# MC3_IPGW_ICONT register map
Vendor: Texas Instruments
Peripheral module from a debugger description file (folder DRA74xP_75xP_76xP_77xP).
Registers are 32-bit, access not given, reset 0x0 unless marked. A register's access mark holds for its fields unless they carry their own. Offsets are as the file gives them; lines under a group give offsets from that group; [hi:lo] are bit positions; {n}, {i} and the like mark numbered series; 'fields as' and 'values as' point back to an identical list; <NAME> marks a mode.

## MC3_IPGW_ICONT
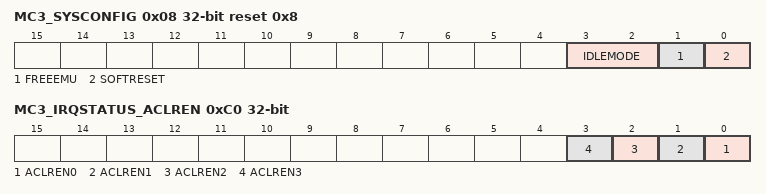
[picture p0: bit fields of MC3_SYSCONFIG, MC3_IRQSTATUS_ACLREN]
0x08 MC3_SYSCONFIG access per field reset 0x8 — Clock management configuration
  [3:2] IDLEMODE rw — Configuration of the local target state management mode.By definition, target can handle read/write transaction as long as it is out of IDLE state . Backup mode, for debug only . Backup mode, for debug only . IP module must not generate (IRQ- or DMA-request-related) wake-up events. . IP module may generate (IRQ- or DMA-request-related) wake-up events when in IDLE state. . Mode is relevant only if the appropriate IP module swakeup output(s) is (are) implemented. .
    0=IDLE_IDLE_IP_0 (Force-idle mode: Local target IDLE state follows (acknowledges) the system IDLE requests unconditionally, that is, regardless of IP module internal requirements.); 1=IDLE_1 (No-idle mode: Local target never enters IDLE state.); 2=IDLE_IP_2 (Smart-idle mode: Local target IDLE state eventually follows (acknowledges) the system idle requests, depending on the IP module internal requirements.); 3=IDLE_IDLE_IP_3 (Smart-idle wake-up-capable mode: Local target IDLE state eventually follows (acknowledges) the system IDLE requests, depending on the IP module internal requirements.)
  [1] FREEEMU rw — Sensitivity to emulation (debug) suspend input signal
    0=IP_0 (IP module is sensitive to emulation suspend.); 1=IP_1 (IP module is not sensitive to emulation suspend.)
  [0] SOFTRESET rw — Software reset
    0=Reset_done,_no_pending_action; 1=Reset_(software_or_other)_ongoing; 0=No_action; 1=Initiate_software_reset
0x0C MC3_IRQ_EOI access per field — End Of Interrupt number specification
  [1:0] LINE_NUMBER rw — Software End Of Interrupt (EOI) control. Write number of interrupt output.
    {v}=EOI_for_interrupt_output_line_#{v} (v=0..3); 0=Reads_always_0_(no_EOI_memory)
{0x14+4i} MC3_IRQSTATUS_RAW_{i} (i=0..3) — Per-event raw interrupt status vector, line {i}. Raw status is set even if event is not enabled. Write 1 to set the (raw) status, mostly for debug.
  [0] EVENT0 — Settable raw status for event 0 Write 0: No action Read 0: No event pending Read 1: Event pending Write 1: Set event (debug). (access RW W1toSet)
{0x30+4i} MC3_IRQSTATUS_{i} (i=0..3) — Per-event enabled interrupt status vector, line {i}. Enabled status is not set unless event is enabled. Write 1 to clear the status after interrupt has been serviced (raw status is cleared; that is, even if not enabled).
  [0] EVENT0 — Clearable, enabled status for event 0 Write 0: No action Read 0: No (enabled) event pending Read 1: Event pending Write 1: Clear (raw) event. (access RW W1toClr)
0x4C MC3_IRQENABLE_SET_0 — Per-event interrupt enable bit vector, line 0. Write 1 to set (enable interrupt). Readout equal to corresponding _CLR register.
  [0] ENABLE0 — Enable for event 0 Write 0: No action Read 0: Interrupt disabled (masked) Read 1: Interrupt enabled Write 1: Enable interrupt (access RW W1toSet)
0x50 MC3_IRQENABLE_SET_1 — Per-event interrupt enable bit vector, line 1. Write 1 to set (enable interrupt). Readout equal to corresponding _CLR register.
  fields as MC3_IRQENABLE_SET_0
0x54 MC3_IRQENABLE_SET_2 — Per-event interrupt enable bit vector, line 2. Write 1 to set (enable interrupt). Readout equal to corresponding _CLR register.
  [0] ENABLE0 — Enable for event 0 Write 0: No action Read 0: Interrupt disabled (masked) Read 1: Interrupt enabled Write 1: Enable interrup..t (access RW W1toSet)
0x58 MC3_IRQENABLE_SET_3 — Per-event interrupt enable bit vector, line 0. Write 1 to set (enable interrupt). Readout equal to corresponding _CLR register.
  [0] ENABLE0 — Enable for event 0 Write 0: No action Read 0: Interrupt disabled (masked) Read 1: Interrupt enabled Write 1: Enable interrupt. (access RW W1toSet)
{0x68+4i} MC3_IRQENABLE_CLR_{i} (i=0..2) — Per-event interrupt enable bit vector, line {i}. Write 1 to clear (disable interrupt). Readout equal to corresponding _SET register.
  [0] ENABLE0 — Enable for event 0 Write 0: No action Read 0: Interrupt disabled (masked) Read 1: Interrupt enabled Write 1: Disable interrupt. (access RW W1toClr)
0x74 MC3_IRQENABLE_CLR_3 — Per-event interrupt enable bit vector, line 2. Write 1 to clear (disable interrupt). Readout equal to corresponding _SET register.
  fields as MC3_IRQENABLE_CLR_0
0xC0 MC3_IRQSTATUS_ACLREN access per field — Auto clear enable
  [n] ACLREN{n} rw (n=0..3) — For line {n}
